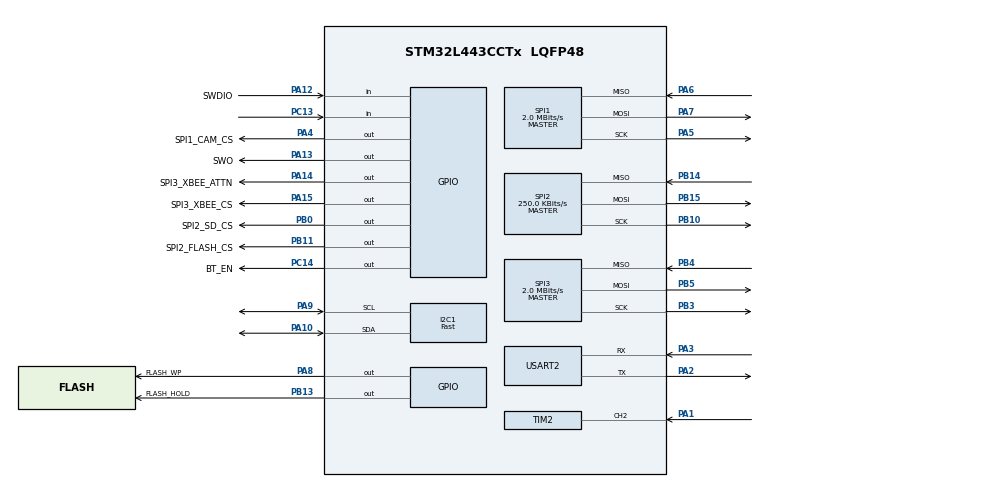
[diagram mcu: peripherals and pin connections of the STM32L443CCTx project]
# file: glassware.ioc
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I2C1.AddressingMode=I2C_ADDRESSINGMODE_7BIT
I2C1.I2C_Speed_Mode=I2C_Fast
I2C1.Timing=0x00000004
Mcu.Family=STM32L4
Mcu.Name=STM32L443CCTx
Mcu.Package=LQFP48
NVIC.PriorityGroup=NVIC_PRIORITYGROUP_4
PA1.Signal=S_TIM2_CH2
PA10.GPIO_Pu=GPIO_PULLUP
PA10.Mode=I2C
PA10.Signal=I2C1_SDA
PA12.GPIO_Label=SWDIO
PA12.Signal=GPIO_Input
PA13\ (JTMS-SWDIO).GPIO_Label=SWO
PA13\ (JTMS-SWDIO).Signal=GPIO_Output
PA14\ (JTCK-SWCLK).GPIO_Label=SPI3_XBEE_ATTN
PA14\ (JTCK-SWCLK).Signal=GPIO_Output
PA15\ (JTDI).GPIO_Label=SPI3_XBEE_CS
PA15\ (JTDI).Signal=GPIO_Output
PA2.Mode=Asynchronous
PA2.Signal=USART2_TX
PA3.Mode=Asynchronous
PA3.Signal=USART2_RX
PA4.GPIO_Label=SPI1_CAM_CS
PA4.Signal=GPIO_Output
PA5.Mode=Full_Duplex_Master
PA5.Signal=SPI1_SCK
PA6.Mode=Full_Duplex_Master
PA6.Signal=SPI1_MISO
PA7.Mode=Full_Duplex_Master
PA7.Signal=SPI1_MOSI
PA8.GPIO_Label=FLASH_WP
PA8.Signal=GPIO_Output
PA9.GPIO_Pu=GPIO_PULLUP
PA9.Mode=I2C
PA9.Signal=I2C1_SCL
PB0.GPIO_Label=SPI2_SD_CS
PB0.Signal=GPIO_Output
PB10.Mode=Full_Duplex_Master
PB10.Signal=SPI2_SCK
PB11.GPIO_Label=SPI2_FLASH_CS
PB11.Signal=GPIO_Output
PB13.GPIO_Label=FLASH_HOLD
PB13.Signal=GPIO_Output
PB14.Mode=Full_Duplex_Master
PB14.Signal=SPI2_MISO
PB15.Mode=Full_Duplex_Master
PB15.Signal=SPI2_MOSI
PB3\ (JTDO-TRACESWO).Mode=Full_Duplex_Master
PB3\ (JTDO-TRACESWO).Signal=SPI3_SCK
PB4\ (NJTRST).Mode=Full_Duplex_Master
PB4\ (NJTRST).Signal=SPI3_MISO
PB5.Mode=Full_Duplex_Master
PB5.Signal=SPI3_MOSI
PC13.Signal=GPIO_Input
PC14-OSC32_IN\ (PC14).GPIO_Label=BT_EN
PC14-OSC32_IN\ (PC14).Signal=GPIO_Output
ProjectManager.HeapSize=0x200
ProjectManager.StackSize=0x400
ProjectManager.TargetToolchain=STM32CubeIDE
RCC.HSE_VALUE=8000000
RCC.HSI48_VALUE=48000000
RCC.HSI_VALUE=16000000
RCC.LSE_VALUE=32768
RCC.MSI_VALUE=4000000
RCC.VCOOutputFreq_Value=32000000
SH.S_TIM2_CH2.0=TIM2_CH2,Input_Capture2_from_TI2
SPI1.CalculateBaudRate=2.0 MBits/s
SPI1.Direction=SPI_DIRECTION_2LINES
SPI1.Mode=SPI_MODE_MASTER
SPI1.VirtualType=VM_MASTER
SPI2.BaudRatePrescaler=SPI_BAUDRATEPRESCALER_16
SPI2.CalculateBaudRate=250.0 KBits/s
SPI2.DataSize=SPI_DATASIZE_8BIT
SPI2.Direction=SPI_DIRECTION_2LINES
SPI2.Mode=SPI_MODE_MASTER
SPI2.VirtualType=VM_MASTER
SPI3.CalculateBaudRate=2.0 MBits/s
SPI3.Direction=SPI_DIRECTION_2LINES
SPI3.Mode=SPI_MODE_MASTER
SPI3.VirtualType=VM_MASTER
TIM2.Channel-Input_Capture2_from_TI2=TIM_CHANNEL_2
USART2.VirtualMode-Asynchronous=VM_ASYNC
VP_FATFS_VS_Generic.Mode=User_defined
VP_TIM2_VS_ClockSourceINT.Mode=Internal
board=custom

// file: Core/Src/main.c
/* USER CODE BEGIN Header */
/**
  ******************************************************************************
  * @file           : main.c
  * @brief          : Main program body
  ******************************************************************************
  * @attention
  *
  * Copyright (c) 2023 STMicroelectronics.
  * All rights reserved.
  *
  * This software is licensed under terms that can be found in the LICENSE file
  * in the root directory of this software component.
  * If no LICENSE file comes with this software, it is provided AS-IS.
  *
  ******************************************************************************
  */
/* USER CODE END Header */
#include "main.h"
#include "fatfs.h"

/* USER CODE BEGIN Includes */
#include "ssd1306.h"
#include "fonts.h"
#include "fatfs_sd.h"
#include <string.h>

/* USER CODE END Includes */

/* USER CODE BEGIN PD */
#define DEBUG

#define SD_SPI_HANDLE hspi2
#define SD_CS_GPIO_Port 'B'
#define SD_CS_GPIO_Pin 0

/* USER CODE END PD */

I2C_HandleTypeDef hi2c1;

SPI_HandleTypeDef hspi1;
SPI_HandleTypeDef hspi2;
SPI_HandleTypeDef hspi3;

TIM_HandleTypeDef htim2;

UART_HandleTypeDef huart2;

/* USER CODE BEGIN PV */
enum menuState {dir = 0, sel_start = 1, sel_dest = 2};
/* USER CODE END PV */

void SystemClock_Config(void);
static void MX_GPIO_Init(void);
static void MX_I2C1_Init(void);
static void MX_SPI2_Init(void);
static void MX_TIM2_Init(void);
static void MX_USART2_UART_Init(void);
static void MX_SPI3_Init(void);
static void MX_SPI1_Init(void);

int main(void)
{

  /* MCU Configuration--------------------------------------------------------*/

  /* Reset of all peripherals, Initializes the Flash interface and the Systick. */
  HAL_Init();

  /* Configure the system clock */
  SystemClock_Config();

  /* Initialize all configured peripherals */
  MX_GPIO_Init();
  MX_I2C1_Init();
  MX_FATFS_Init();
  MX_SPI2_Init();
  MX_TIM2_Init();
  MX_USART2_UART_Init();
  MX_SPI3_Init();
  MX_SPI1_Init();
  /* USER CODE BEGIN 2 */

  // Initialize screen
//  enum menuState menu = dir;
//  SSD1306_Init();
//  SSD1306_GotoXY (0,0);
//  SSD1306_Puts ("HEPL", &Font_11x18, 1);
//  SSD1306_UpdateScreen(); //display
//  HAL_Delay(4000);
//
//  // Initialize SD card
//  // some variables for FatFs
//  FATFS FatFs; 	//Fatfs handle
//  FIL fil; 		//File handle
//  FRESULT fres; //Result after operations
//  string filename = "test.txt";
//
//  fres = f_mount(&FatFs, "", 1); // 1 = mount now
//  if (fres != FR_OK)
//  {
//      #ifdef DEBUG
//	  SSD1306_GotoXY (0,0);
//	  SSD1306_Puts ("ErrSD-Mnt", &Font_11x18, 1); // error mounting
//	  SSD1306_UpdateScreen(); //display
//      #endif
//	  while(1);
//  }
//
//  #ifdef DEBUG
//  DWORD free_clusters, free_sectors, total_sectors;
//  FATFS* getFreeFs;
//  fres = f_getfree("", &free_clusters, &getFreeFs);
//  if (fres != FR_OK)
//  {
//	  SSD1306_GotoXY (0,0);
//	  SSD1306_Puts ("ErrSD-GFr", &Font_11x18, 1); // error getting free
//	  SSD1306_UpdateScreen(); //display
//	  while(1);
//  }
//  total_sectors = (getFreeFs->n_fatent - 2) * getFreeFs->csize;
//  free_sectors = free_clusters * getFreeFs->csize;
//  #endif
//
//  fres = f_open(&fil, filename, FA_READ);
//  if (fres != FR_OK) {
//      #ifdef DEBUG
//	  SSD1306_GotoXY (0,0);
//	  SSD1306_Puts ("ErrSD-OpF", &Font_11x18, 1); // error opening file
//	  SSD1306_UpdateScreen();
// 	  #endif
//	  while(1);
//  }
//
//  BYTE readBuf[30];
//  TCHAR* rres = f_gets((TCHAR*)readBuf, 30, &fil);
//  if (rres == 0)
//  {
//      #ifdef DEBUG
//	  SSD1306_GotoXY (0,0);
//	  SSD1306_Puts ("ErrSD-RdF", &Font_11x18, 1); // error reading file
//	  SSD1306_UpdateScreen();
//      #endif
//	  while(1);
//  }
//  f_close(&fil);
//  #ifdef DEBUG
//  SSD1306_GotoXY (0,0);
//  SSD1306_Puts(strcat("File: ", filename), &Font_11x18, 1);
//  SSD1306_GotoXY (11,0);
//  SSD1306_Puts(readBuf, &Font_11x18, 1);
//  SSD1306_UpdateScreen();
//  HAL_Delay(2000);
//  #endif

  /* USER CODE END 2 */

  /* Infinite loop */
  while (1)
  {

    /* USER CODE BEGIN 3 */
	  SSD1306_Init();
	  SSD1306_GotoXY (0,21);
	  SSD1306_Puts ("HELLO WORLD :)", &Font_7x10, 1);
	  SSD1306_UpdateScreen(); //display

	  HAL_Delay (2000);
  }
  /* USER CODE END 3 */
}

void SystemClock_Config(void)
{
  RCC_OscInitTypeDef RCC_OscInitStruct = {0};
  RCC_ClkInitTypeDef RCC_ClkInitStruct = {0};

  /** Configure the main internal regulator output voltage
  */
  if (HAL_PWREx_ControlVoltageScaling(PWR_REGULATOR_VOLTAGE_SCALE1) != HAL_OK)
  {
    Error_Handler();
  }

  /** Initializes the RCC Oscillators according to the specified parameters
  * in the RCC_OscInitTypeDef structure.
  */
  RCC_OscInitStruct.OscillatorType = RCC_OSCILLATORTYPE_MSI;
  RCC_OscInitStruct.MSIState = RCC_MSI_ON;
  RCC_OscInitStruct.MSICalibrationValue = 0;
  RCC_OscInitStruct.MSIClockRange = RCC_MSIRANGE_6;
  RCC_OscInitStruct.PLL.PLLState = RCC_PLL_NONE;
  if (HAL_RCC_OscConfig(&RCC_OscInitStruct) != HAL_OK)
  {
    Error_Handler();
  }

  /** Initializes the CPU, AHB and APB buses clocks
  */
  RCC_ClkInitStruct.ClockType = RCC_CLOCKTYPE_HCLK|RCC_CLOCKTYPE_SYSCLK
                              |RCC_CLOCKTYPE_PCLK1|RCC_CLOCKTYPE_PCLK2;
  RCC_ClkInitStruct.SYSCLKSource = RCC_SYSCLKSOURCE_MSI;
  RCC_ClkInitStruct.AHBCLKDivider = RCC_SYSCLK_DIV1;
  RCC_ClkInitStruct.APB1CLKDivider = RCC_HCLK_DIV1;
  RCC_ClkInitStruct.APB2CLKDivider = RCC_HCLK_DIV1;

  if (HAL_RCC_ClockConfig(&RCC_ClkInitStruct, FLASH_LATENCY_0) != HAL_OK)
  {
    Error_Handler();
  }
}

static void MX_I2C1_Init(void)
{

  hi2c1.Instance = I2C1;
  hi2c1.Init.Timing = 0x00000004;
  hi2c1.Init.OwnAddress1 = 0;
  hi2c1.Init.AddressingMode = I2C_ADDRESSINGMODE_7BIT;
  hi2c1.Init.DualAddressMode = I2C_DUALADDRESS_DISABLE;
  hi2c1.Init.OwnAddress2 = 0;
  hi2c1.Init.OwnAddress2Masks = I2C_OA2_NOMASK;
  hi2c1.Init.GeneralCallMode = I2C_GENERALCALL_DISABLE;
  hi2c1.Init.NoStretchMode = I2C_NOSTRETCH_DISABLE;
  if (HAL_I2C_Init(&hi2c1) != HAL_OK)
  {
    Error_Handler();
  }

  /** Configure Analogue filter
  */
  if (HAL_I2CEx_ConfigAnalogFilter(&hi2c1, I2C_ANALOGFILTER_ENABLE) != HAL_OK)
  {
    Error_Handler();
  }

  /** Configure Digital filter
  */
  if (HAL_I2CEx_ConfigDigitalFilter(&hi2c1, 0) != HAL_OK)
  {
    Error_Handler();
  }

}

static void MX_SPI1_Init(void)
{

  /* SPI1 parameter configuration*/
  hspi1.Instance = SPI1;
  hspi1.Init.Mode = SPI_MODE_MASTER;
  hspi1.Init.Direction = SPI_DIRECTION_2LINES;
  hspi1.Init.DataSize = SPI_DATASIZE_4BIT;
  hspi1.Init.CLKPolarity = SPI_POLARITY_LOW;
  hspi1.Init.CLKPhase = SPI_PHASE_1EDGE;
  hspi1.Init.NSS = SPI_NSS_SOFT;
  hspi1.Init.BaudRatePrescaler = SPI_BAUDRATEPRESCALER_2;
  hspi1.Init.FirstBit = SPI_FIRSTBIT_MSB;
  hspi1.Init.TIMode = SPI_TIMODE_DISABLE;
  hspi1.Init.CRCCalculation = SPI_CRCCALCULATION_DISABLE;
  hspi1.Init.CRCPolynomial = 7;
  hspi1.Init.CRCLength = SPI_CRC_LENGTH_DATASIZE;
  hspi1.Init.NSSPMode = SPI_NSS_PULSE_ENABLE;
  if (HAL_SPI_Init(&hspi1) != HAL_OK)
  {
    Error_Handler();
  }

}

static void MX_SPI2_Init(void)
{

  /* SPI2 parameter configuration*/
  hspi2.Instance = SPI2;
  hspi2.Init.Mode = SPI_MODE_MASTER;
  hspi2.Init.Direction = SPI_DIRECTION_2LINES;
  hspi2.Init.DataSize = SPI_DATASIZE_8BIT;
  hspi2.Init.CLKPolarity = SPI_POLARITY_LOW;
  hspi2.Init.CLKPhase = SPI_PHASE_1EDGE;
  hspi2.Init.NSS = SPI_NSS_SOFT;
  hspi2.Init.BaudRatePrescaler = SPI_BAUDRATEPRESCALER_16;
  hspi2.Init.FirstBit = SPI_FIRSTBIT_MSB;
  hspi2.Init.TIMode = SPI_TIMODE_DISABLE;
  hspi2.Init.CRCCalculation = SPI_CRCCALCULATION_DISABLE;
  hspi2.Init.CRCPolynomial = 7;
  hspi2.Init.CRCLength = SPI_CRC_LENGTH_DATASIZE;
  hspi2.Init.NSSPMode = SPI_NSS_PULSE_ENABLE;
  if (HAL_SPI_Init(&hspi2) != HAL_OK)
  {
    Error_Handler();
  }

}

static void MX_SPI3_Init(void)
{

  /* SPI3 parameter configuration*/
  hspi3.Instance = SPI3;
  hspi3.Init.Mode = SPI_MODE_MASTER;
  hspi3.Init.Direction = SPI_DIRECTION_2LINES;
  hspi3.Init.DataSize = SPI_DATASIZE_4BIT;
  hspi3.Init.CLKPolarity = SPI_POLARITY_LOW;
  hspi3.Init.CLKPhase = SPI_PHASE_1EDGE;
  hspi3.Init.NSS = SPI_NSS_SOFT;
  hspi3.Init.BaudRatePrescaler = SPI_BAUDRATEPRESCALER_2;
  hspi3.Init.FirstBit = SPI_FIRSTBIT_MSB;
  hspi3.Init.TIMode = SPI_TIMODE_DISABLE;
  hspi3.Init.CRCCalculation = SPI_CRCCALCULATION_DISABLE;
  hspi3.Init.CRCPolynomial = 7;
  hspi3.Init.CRCLength = SPI_CRC_LENGTH_DATASIZE;
  hspi3.Init.NSSPMode = SPI_NSS_PULSE_ENABLE;
  if (HAL_SPI_Init(&hspi3) != HAL_OK)
  {
    Error_Handler();
  }

}

static void MX_TIM2_Init(void)
{

  TIM_ClockConfigTypeDef sClockSourceConfig = {0};
  TIM_MasterConfigTypeDef sMasterConfig = {0};
  TIM_IC_InitTypeDef sConfigIC = {0};

  htim2.Instance = TIM2;
  htim2.Init.Prescaler = 0;
  htim2.Init.CounterMode = TIM_COUNTERMODE_UP;
  htim2.Init.Period = 4294967295;
  htim2.Init.ClockDivision = TIM_CLOCKDIVISION_DIV1;
  htim2.Init.AutoReloadPreload = TIM_AUTORELOAD_PRELOAD_DISABLE;
  if (HAL_TIM_Base_Init(&htim2) != HAL_OK)
  {
    Error_Handler();
  }
  sClockSourceConfig.ClockSource = TIM_CLOCKSOURCE_INTERNAL;
  if (HAL_TIM_ConfigClockSource(&htim2, &sClockSourceConfig) != HAL_OK)
  {
    Error_Handler();
  }
  if (HAL_TIM_IC_Init(&htim2) != HAL_OK)
  {
    Error_Handler();
  }
  sMasterConfig.MasterOutputTrigger = TIM_TRGO_RESET;
  sMasterConfig.MasterSlaveMode = TIM_MASTERSLAVEMODE_DISABLE;
  if (HAL_TIMEx_MasterConfigSynchronization(&htim2, &sMasterConfig) != HAL_OK)
  {
    Error_Handler();
  }
  sConfigIC.ICPolarity = TIM_INPUTCHANNELPOLARITY_RISING;
  sConfigIC.ICSelection = TIM_ICSELECTION_DIRECTTI;
  sConfigIC.ICPrescaler = TIM_ICPSC_DIV1;
  sConfigIC.ICFilter = 0;
  if (HAL_TIM_IC_ConfigChannel(&htim2, &sConfigIC, TIM_CHANNEL_2) != HAL_OK)
  {
    Error_Handler();
  }

}

static void MX_USART2_UART_Init(void)
{

  huart2.Instance = USART2;
  huart2.Init.BaudRate = 115200;
  huart2.Init.WordLength = UART_WORDLENGTH_8B;
  huart2.Init.StopBits = UART_STOPBITS_1;
  huart2.Init.Parity = UART_PARITY_NONE;
  huart2.Init.Mode = UART_MODE_TX_RX;
  huart2.Init.HwFlowCtl = UART_HWCONTROL_NONE;
  huart2.Init.OverSampling = UART_OVERSAMPLING_16;
  huart2.Init.OneBitSampling = UART_ONE_BIT_SAMPLE_DISABLE;
  huart2.AdvancedInit.AdvFeatureInit = UART_ADVFEATURE_NO_INIT;
  if (HAL_UART_Init(&huart2) != HAL_OK)
  {
    Error_Handler();
  }

}

static void MX_GPIO_Init(void)
{
  GPIO_InitTypeDef GPIO_InitStruct = {0};

  /* GPIO Ports Clock Enable */
  __HAL_RCC_GPIOC_CLK_ENABLE();
  __HAL_RCC_GPIOA_CLK_ENABLE();
  __HAL_RCC_GPIOB_CLK_ENABLE();

  /*Configure GPIO pin Output Level */
  HAL_GPIO_WritePin(BT_EN_GPIO_Port, BT_EN_Pin, GPIO_PIN_RESET);

  /*Configure GPIO pin Output Level */
  HAL_GPIO_WritePin(GPIOA, SPI1_CAM_CS_Pin|FLASH_WP_Pin|SWO_Pin|SPI3_XBEE_ATTN_Pin
                          |SPI3_XBEE_CS_Pin, GPIO_PIN_RESET);

  /*Configure GPIO pin Output Level */
  HAL_GPIO_WritePin(GPIOB, SPI2_SD_CS_Pin|SPI2_FLASH_CS_Pin|FLASH_HOLD_Pin, GPIO_PIN_RESET);

  /*Configure GPIO pin : PC13 */
  GPIO_InitStruct.Pin = GPIO_PIN_13;
  GPIO_InitStruct.Mode = GPIO_MODE_INPUT;
  GPIO_InitStruct.Pull = GPIO_NOPULL;
  HAL_GPIO_Init(GPIOC, &GPIO_InitStruct);

  /*Configure GPIO pin : BT_EN_Pin */
  GPIO_InitStruct.Pin = BT_EN_Pin;
  GPIO_InitStruct.Mode = GPIO_MODE_OUTPUT_PP;
  GPIO_InitStruct.Pull = GPIO_NOPULL;
  GPIO_InitStruct.Speed = GPIO_SPEED_FREQ_LOW;
  HAL_GPIO_Init(BT_EN_GPIO_Port, &GPIO_InitStruct);

  /*Configure GPIO pins : SPI1_CAM_CS_Pin FLASH_WP_Pin SWO_Pin SPI3_XBEE_ATTN_Pin
                           SPI3_XBEE_CS_Pin */
  GPIO_InitStruct.Pin = SPI1_CAM_CS_Pin|FLASH_WP_Pin|SWO_Pin|SPI3_XBEE_ATTN_Pin
                          |SPI3_XBEE_CS_Pin;
  GPIO_InitStruct.Mode = GPIO_MODE_OUTPUT_PP;
  GPIO_InitStruct.Pull = GPIO_NOPULL;
  GPIO_InitStruct.Speed = GPIO_SPEED_FREQ_LOW;
  HAL_GPIO_Init(GPIOA, &GPIO_InitStruct);

  /*Configure GPIO pins : SPI2_SD_CS_Pin SPI2_FLASH_CS_Pin FLASH_HOLD_Pin */
  GPIO_InitStruct.Pin = SPI2_SD_CS_Pin|SPI2_FLASH_CS_Pin|FLASH_HOLD_Pin;
  GPIO_InitStruct.Mode = GPIO_MODE_OUTPUT_PP;
  GPIO_InitStruct.Pull = GPIO_NOPULL;
  GPIO_InitStruct.Speed = GPIO_SPEED_FREQ_LOW;
  HAL_GPIO_Init(GPIOB, &GPIO_InitStruct);

  /*Configure GPIO pin : SWDIO_Pin */
  GPIO_InitStruct.Pin = SWDIO_Pin;
  GPIO_InitStruct.Mode = GPIO_MODE_INPUT;
  GPIO_InitStruct.Pull = GPIO_NOPULL;
  HAL_GPIO_Init(SWDIO_GPIO_Port, &GPIO_InitStruct);

}

void Error_Handler(void)
{
  __disable_irq();
  while (1)
  {
  }
}
